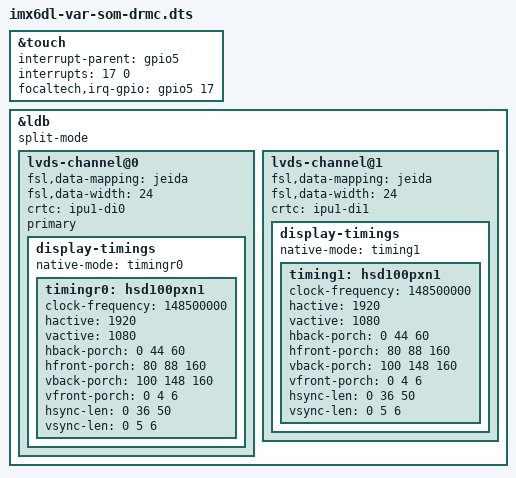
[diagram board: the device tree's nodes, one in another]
/*
 * Copyright (C) 2016 Variscite, Ltd. All Rights Reserved
 * 
 * This program is free software; you can redistribute it and/or modify
 * it under the terms of the GNU General Public License version 2 as
 * published by the Free Software Foundation.
 */

#include "imx6dl-var-som.dtsi"
#include "imx6qdl-var-solocb-dt6cb-displays.dtsi"


&touch {
	interrupt-parent = <&gpio5>;
	interrupts = <17 0>;
	focaltech,irq-gpio = <&gpio5 17 0x00>;
};


&ldb {
	status = "okay";
	split-mode;
	lvds-channel@0 {
		fsl,data-mapping = "jeida";
		fsl,data-width = <24>;
		crtc = "ipu1-di0";
		primary;
		status = "okay";

	display-timings {
			native-mode = <&timingr0>;
			timingr0: hsd100pxn1 {
				clock-frequency = <148500000>;
				hactive = <1920>;
				vactive = <1080>;
				hback-porch = <0 44 60>;
				hfront-porch = <80 88 160>;
				vback-porch = <100 148 160>;
				vfront-porch = <0 4 6>;
				hsync-len = <0 36 50>;
				vsync-len = <0 5 6>;
			};
		};
	};

	lvds-channel@1 {
		fsl,data-mapping = "jeida";
		fsl,data-width = <24>;
		crtc = "ipu1-di1";
		status = "okay";

		display-timings {
			native-mode = <&timing1>;
			timing1: hsd100pxn1 {
				clock-frequency = <148500000>;
				hactive = <1920>;
				vactive = <1080>;
				hback-porch = <0 44 60>;
				hfront-porch = <80 88 160>;
				vback-porch = <100 148 160>;
				vfront-porch = <0 4 6>;
				hsync-len = <0 36 50>;
				vsync-len = <0 5 6>;
			};
		};
	};
};

